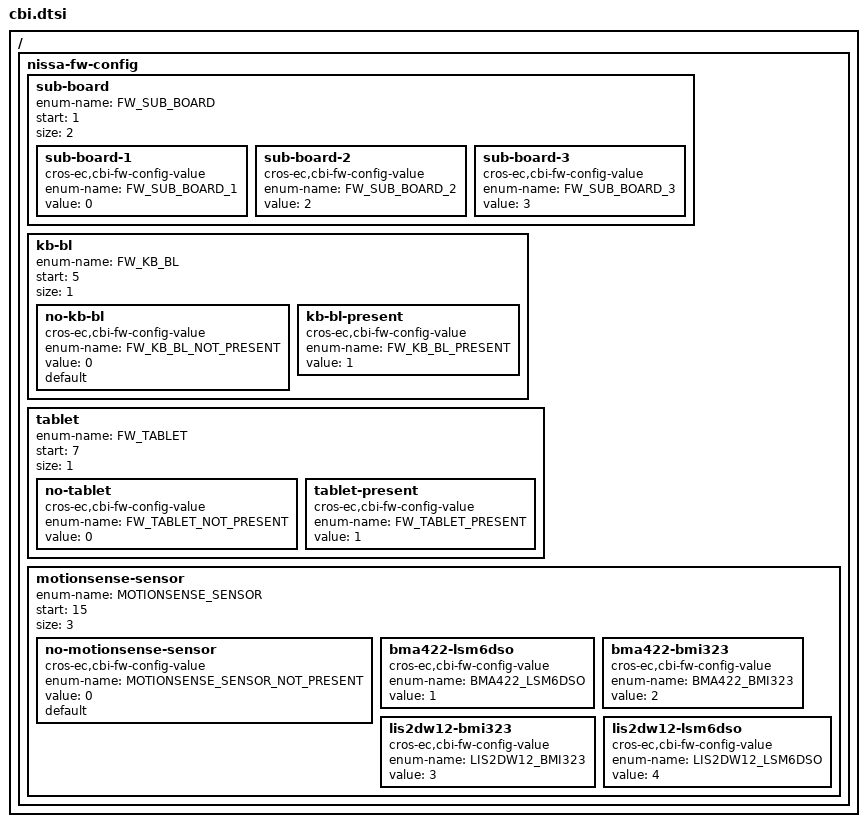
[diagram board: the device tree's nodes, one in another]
/* Copyright 2023 The ChromiumOS Authors
 * Use of this source code is governed by a BSD-style license that can be
 * found in the LICENSE file.
 */

/ {
  /* Uldren-specific fw_config fields. */
	nissa-fw-config {
		/*
		 * FW_CONFIG field to enable USB DB.
		 */
		sub-board {
			enum-name = "FW_SUB_BOARD";
			start = <1>;
			size = <2>;

			sub-board-1 {
				compatible = "cros-ec,cbi-fw-config-value";
				enum-name = "FW_SUB_BOARD_1";
				value = <0>;
			};
			sub-board-2 {
				compatible = "cros-ec,cbi-fw-config-value";
				enum-name = "FW_SUB_BOARD_2";
				value = <2>;
			};
			sub-board-3 {
				compatible = "cros-ec,cbi-fw-config-value";
				enum-name = "FW_SUB_BOARD_3";
				value = <3>;
			};
		};
		/*
		 * FW_CONFIG field to enable KB back light or not.
		 */
		kb-bl {
			enum-name = "FW_KB_BL";
			start = <5>;
			size = <1>;

			no-kb-bl {
				compatible = "cros-ec,cbi-fw-config-value";
				enum-name = "FW_KB_BL_NOT_PRESENT";
				value = <0>;
				default;
			};
			kb-bl-present {
				compatible = "cros-ec,cbi-fw-config-value";
				enum-name = "FW_KB_BL_PRESENT";
				value = <1>;
			};
		};

		/*
		 * FW_CONFIG field for tablet present or not.
		 */
		 tablet {
			enum-name = "FW_TABLET";
			start = <7>;
			size = <1>;

			no-tablet {
				compatible = "cros-ec,cbi-fw-config-value";
				enum-name = "FW_TABLET_NOT_PRESENT";
				value = <0>;
			};
			tablet-present {
				compatible = "cros-ec,cbi-fw-config-value";
				enum-name = "FW_TABLET_PRESENT";
				value = <1>;
			};
		};

		/*
		 * FW_CONFIG field to identify motion sensor.
		 */
		motionsense-sensor {
			enum-name = "MOTIONSENSE_SENSOR";
			start = <15>;
			size = <3>;

			no-motionsense-sensor {
				compatible = "cros-ec,cbi-fw-config-value";
				enum-name = "MOTIONSENSE_SENSOR_NOT_PRESENT";
				value = <0>;
				default;
			};
			bma422-lsm6dso {
				compatible = "cros-ec,cbi-fw-config-value";
				enum-name = "BMA422_LSM6DSO";
				value = <1>;
			};
			bma422-bmi323 {
				compatible = "cros-ec,cbi-fw-config-value";
				enum-name = "BMA422_BMI323";
				value = <2>;
			};
			lis2dw12-bmi323 {
				compatible = "cros-ec,cbi-fw-config-value";
				enum-name = "LIS2DW12_BMI323";
				value = <3>;
			};
			lis2dw12-lsm6dso {
				compatible = "cros-ec,cbi-fw-config-value";
				enum-name = "LIS2DW12_LSM6DSO";
				value = <4>;
			};
		};

/delete-node/ fan;
	};
};
